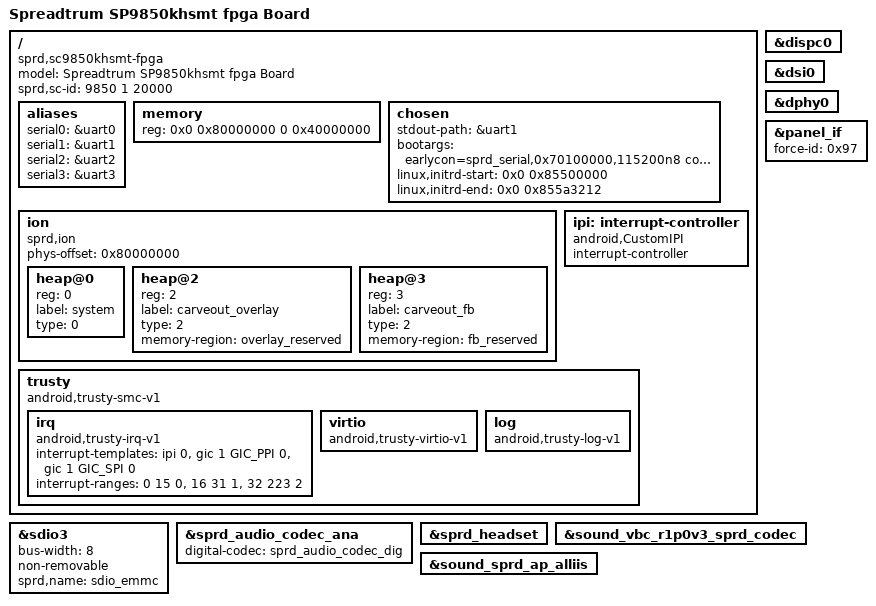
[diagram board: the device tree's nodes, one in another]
/*
 * Spreadtrum SP9850KH board DTS file
 *
 * Copyright (C) 2016, Spreadtrum Communications Inc.
 *
 * This file is licensed under a dual GPLv2 or X11 license.
 */

/dts-v1/;

#include "sc9850khsmt.dtsi"
#include "sp9850kh-common.dtsi"

/ {
	model = "Spreadtrum SP9850khsmt fpga Board";

	compatible = "sprd,sc9850khsmt-fpga";

	sprd,sc-id = <9850 1 20000>;

	aliases {
		serial0 = &uart0;
		serial1 = &uart1;
		serial2 = &uart2;
		serial3 = &uart3;
	};

	memory{
		device_type = "memory";
		reg = <0x0 0x80000000 0 0x40000000>;
	};

	chosen {
		stdout-path = &uart1;
		bootargs = "earlycon=sprd_serial,0x70100000,115200n8 console=ttyS1,115200n8 loglevel=8 androidboot.hardware=j1fpga memblock=debug bootmem_debug=1";
		linux,initrd-start = <0x0 0x85500000>; /* this val will be changed by uboot  */
		linux,initrd-end = <0x0 0x855a3212>; /* this val will be changed by uboot  */
	};

	ion {
		compatible = "sprd,ion";
		#address-cells = <1>;
		#size-cells = <0>;
		phys-offset = <0x80000000>;

		heap@0 {
			reg = <0>;
			label = "system";
			type = <0>;
		};

		heap@2 {
			reg = <2>;
			label = "carveout_overlay";
			type = <2>;
			memory-region = <&overlay_reserved>;
		};

		heap@3 {
			reg = <3>;
			label = "carveout_fb";
			type = <2>;
			memory-region = <&fb_reserved>;
		};
	};

	ipi: interrupt-controller {
		compatible = "android,CustomIPI";
		#interrupt-cells = <1>;
		interrupt-controller;
	};

	trusty {
		compatible = "android,trusty-smc-v1";

		irq {
			compatible = "android,trusty-irq-v1";
			interrupt-templates = <&ipi 0>,
						<&gic 1 GIC_PPI 0>,
						<&gic 1 GIC_SPI 0>;
			interrupt-ranges = < 0  15 0>,
						<16  31 1>,
						<32 223 2>;
		};

		virtio {
			compatible = "android,trusty-virtio-v1";
		};

		log {
			compatible = "android,trusty-log-v1";
		};
	};

};

&dispc0 {
	status = "okay";
};

&dsi0 {
	status = "okay";
};

&dphy0 {
	status = "okay";
};

&panel_if {
	force-id = <0x97>;
};

&sdio3 {
	bus-width = <8>;
	non-removable;
	sprd,name = "sdio_emmc";
	status = "okay";
};

&sprd_audio_codec_ana {
	status = "okay";
	digital-codec = <&sprd_audio_codec_dig>;
};

&sprd_headset {
	status = "okay";
};

&sound_vbc_r1p0v3_sprd_codec {
	status = "okay";
};

&sound_sprd_ap_alliis {
	status = "okay";
};
